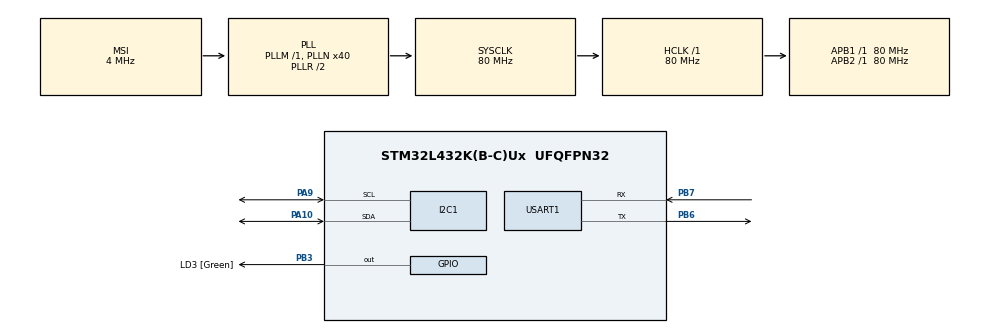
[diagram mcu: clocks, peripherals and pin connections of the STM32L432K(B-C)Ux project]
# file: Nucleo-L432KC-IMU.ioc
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Dma.Request0=USART1_RX
Dma.USART1_RX.0.Direction=DMA_PERIPH_TO_MEMORY
Dma.USART1_RX.0.Instance=DMA1_Channel5
Dma.USART1_RX.0.MemDataAlignment=DMA_MDATAALIGN_BYTE
Dma.USART1_RX.0.MemInc=DMA_MINC_ENABLE
Dma.USART1_RX.0.Mode=DMA_CIRCULAR
Dma.USART1_RX.0.PeriphDataAlignment=DMA_PDATAALIGN_BYTE
Dma.USART1_RX.0.PeriphInc=DMA_PINC_DISABLE
Dma.USART1_RX.0.Priority=DMA_PRIORITY_HIGH
FREERTOS.Mutexes01=USART1RXMutex,Static,USART1RXMutexControlBlock;I2C1Mutex,Static,I2C1MutexControlBlock;USART1TXMutex,Static,USART1TXMutexControlBlock
FREERTOS.Queues01=I2C1RXEventQueue,1,uint8_t,0,Static,I2C1RXEventQueueBuffer,I2C1RXEventQueueControlBlock;I2C1TXEventQueue,1,uint8_t,0,Static,I2C1TXEventQueueBuffer,I2C1TXEventQueueControlBlock;USART1RXEventQueue,1,uint8_t,0,Static,USART1RXEventQueueBuffer,USART1RXEventQueueControlBlock
FREERTOS.Tasks01=consoleTask,24,512,ConsoleTask,As weak,NULL,Static,consoleTaskBuffer,consoleTaskControlBlock;memsTask,24,1024,MEMSTask,As weak,NULL,Static,memsTaskBuffer,memsTaskControlBlock
FREERTOS.Timers01=taskTimer,taskTimerCb,osTimerPeriodic,As weak,NULL,Static,taskTimerControlBlock
FREERTOS.configENABLE_FPU=1
FREERTOS.configUSE_NEWLIB_REENTRANT=1
FREERTOS.configUSE_TIMERS=1
I2C1.Timing=0x10909CEC
Mcu.Family=STM32L4
Mcu.Name=STM32L432K(B-C)Ux
Mcu.Package=UFQFPN32
NVIC.DMA1_Channel5_IRQn=true\:5\:0\:false\:false\:true\:true\:false\:true\:true
NVIC.I2C1_EV_IRQn=true\:5\:0\:false\:false\:true\:true\:true\:true\:true
NVIC.PriorityGroup=NVIC_PRIORITYGROUP_4
NVIC.TIM7_IRQn=true\:15\:0\:false\:false\:true\:false\:false\:true\:true
NVIC.TimeBase=TIM7_IRQn
NVIC.TimeBaseIP=TIM7
NVIC.USART1_IRQn=true\:5\:0\:false\:false\:true\:true\:true\:true\:true
PA0.GPIO_Label=MCO [High speed clock in]
PA0.Signal=RCC_CK_IN
PA10.Mode=I2C
PA10.Signal=I2C1_SDA
PA13\ (JTMS-SWDIO).GPIO_Label=SWDIO
PA13\ (JTMS-SWDIO).Signal=SYS_JTMS-SWDIO
PA14\ (JTCK-SWCLK).GPIO_Label=SWCLK
PA14\ (JTCK-SWCLK).Signal=SYS_JTCK-SWCLK
PA15\ (JTDI).GPIO_Label=VCP_RX
PA15\ (JTDI).Signal=USART2_RX
PA2.GPIO_Label=VCP_TX
PA2.Signal=USART2_TX
PA9.Mode=I2C
PA9.Signal=I2C1_SCL
PB3\ (JTDO-TRACESWO).GPIO_Label=LD3 [Green]
PB3\ (JTDO-TRACESWO).Signal=GPIO_Output
PB6.Mode=Asynchronous
PB6.Signal=USART1_TX
PB7.Mode=Asynchronous
PB7.Signal=USART1_RX
PC14-OSC32_IN\ (PC14).Signal=RCC_OSC32_IN
PC15-OSC32_OUT\ (PC15).Signal=RCC_OSC32_OUT
ProjectManager.HeapSize=0x200
ProjectManager.StackSize=0x400
ProjectManager.TargetToolchain=STM32CubeIDE
RCC.AHBFreq_Value=80000000
RCC.APB1Freq_Value=80000000
RCC.APB1TimFreq_Value=80000000
RCC.APB2Freq_Value=80000000
RCC.APB2TimFreq_Value=80000000
RCC.CortexFreq_Value=80000000
RCC.HCLKFreq_Value=80000000
RCC.HSE_VALUE=8000000
RCC.HSI16_VALUE=16000000
RCC.HSI48_VALUE=48000000
RCC.HSI_VALUE=16000000
RCC.LSE_VALUE=32768
RCC.MSI_VALUE=4000000
RCC.PLLMUL=RCC_PLLMUL_4
RCC.PLLN=40
RCC.SYSCLKFreq_VALUE=80000000
RCC.SYSCLKSource=RCC_SYSCLKSOURCE_PLLCLK
RCC.VCOOutputFreq_Value=160000000
USART1.VirtualMode-Asynchronous=VM_ASYNC
VP_CRC_VS_CRC.Mode=CRC_Activate
VP_FREERTOS_VS_CMSIS_V2.Mode=CMSIS_V2
VP_SYS_VS_tim7.Mode=TIM7
board=NUCLEO-L432KC

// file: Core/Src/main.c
/* USER CODE BEGIN Header */
/**
  ******************************************************************************
  * @file           : main.c
  * @brief          : Main program body
  ******************************************************************************
  * @attention
  *
  * Copyright (c) 2023 STMicroelectronics.
  * All rights reserved.
  *
  * This software is licensed under terms that can be found in the LICENSE file
  * in the root directory of this software component.
  * If no LICENSE file comes with this software, it is provided AS-IS.
  *
  ******************************************************************************
  */
/* USER CODE END Header */
#include "main.h"
#include "cmsis_os.h"
#include "crc.h"
#include "dma.h"
#include "i2c.h"
#include "usart.h"
#include "gpio.h"

/* USER CODE BEGIN Includes */
#include "appMotionFX.h"
/* USER CODE END Includes */

void SystemClock_Config(void);
void MX_FREERTOS_Init(void);

int main(void)
{

  /* MCU Configuration--------------------------------------------------------*/

  /* Reset of all peripherals, Initializes the Flash interface and the Systick. */
  HAL_Init();

  /* Configure the system clock */
  SystemClock_Config();

  /* Initialize all configured peripherals */
  MX_GPIO_Init();
  MX_DMA_Init();
  MX_I2C1_Init();
  MX_USART1_UART_Init();
  MX_CRC_Init();

  /* Init scheduler */
  osKernelInitialize();  /* Call init function for freertos objects (in freertos.c) */
  MX_FREERTOS_Init();

  /* Start scheduler */
  osKernelStart();

  /* We should never get here as control is now taken by the scheduler */
  /* Infinite loop */
  while (1)
  {

  }
}

void SystemClock_Config(void)
{
  RCC_OscInitTypeDef RCC_OscInitStruct = {0};
  RCC_ClkInitTypeDef RCC_ClkInitStruct = {0};

  /** Configure the main internal regulator output voltage
  */
  if (HAL_PWREx_ControlVoltageScaling(PWR_REGULATOR_VOLTAGE_SCALE1) != HAL_OK)
  {
    Error_Handler();
  }

  /** Initializes the RCC Oscillators according to the specified parameters
  * in the RCC_OscInitTypeDef structure.
  */
  RCC_OscInitStruct.OscillatorType = RCC_OSCILLATORTYPE_MSI;
  RCC_OscInitStruct.MSIState = RCC_MSI_ON;
  RCC_OscInitStruct.MSICalibrationValue = 0;
  RCC_OscInitStruct.MSIClockRange = RCC_MSIRANGE_6;
  RCC_OscInitStruct.PLL.PLLState = RCC_PLL_ON;
  RCC_OscInitStruct.PLL.PLLSource = RCC_PLLSOURCE_MSI;
  RCC_OscInitStruct.PLL.PLLM = 1;
  RCC_OscInitStruct.PLL.PLLN = 40;
  RCC_OscInitStruct.PLL.PLLP = RCC_PLLP_DIV7;
  RCC_OscInitStruct.PLL.PLLQ = RCC_PLLQ_DIV2;
  RCC_OscInitStruct.PLL.PLLR = RCC_PLLR_DIV2;
  if (HAL_RCC_OscConfig(&RCC_OscInitStruct) != HAL_OK)
  {
    Error_Handler();
  }

  /** Initializes the CPU, AHB and APB buses clocks
  */
  RCC_ClkInitStruct.ClockType = RCC_CLOCKTYPE_HCLK|RCC_CLOCKTYPE_SYSCLK
                              |RCC_CLOCKTYPE_PCLK1|RCC_CLOCKTYPE_PCLK2;
  RCC_ClkInitStruct.SYSCLKSource = RCC_SYSCLKSOURCE_PLLCLK;
  RCC_ClkInitStruct.AHBCLKDivider = RCC_SYSCLK_DIV1;
  RCC_ClkInitStruct.APB1CLKDivider = RCC_HCLK_DIV1;
  RCC_ClkInitStruct.APB2CLKDivider = RCC_HCLK_DIV1;

  if (HAL_RCC_ClockConfig(&RCC_ClkInitStruct, FLASH_LATENCY_4) != HAL_OK)
  {
    Error_Handler();
  }
}

void HAL_TIM_PeriodElapsedCallback(TIM_HandleTypeDef *htim)
{
  if (htim->Instance == TIM7) {
    HAL_IncTick();
  }
}

void Error_Handler(void)
{
  __disable_irq();
  while (1)
  {
  }
}

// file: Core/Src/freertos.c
/* USER CODE BEGIN Header */
/**
  ******************************************************************************
  * File Name          : freertos.c
  * Description        : Code for freertos applications
  ******************************************************************************
  * @attention
  *
  * Copyright (c) 2023 STMicroelectronics.
  * All rights reserved.
  *
  * This software is licensed under terms that can be found in the LICENSE file
  * in the root directory of this software component.
  * If no LICENSE file comes with this software, it is provided AS-IS.
  *
  ******************************************************************************
  */
/* USER CODE END Header */

#include "FreeRTOS.h"
#include "task.h"
#include "main.h"
#include "cmsis_os.h"

/* USER CODE BEGIN Includes */
#include "appLSM9DS1.h"
#include "appI2C.h"
#include "appUSART.h"
#include "console.h"
/* USER CODE END Includes */

typedef StaticTask_t osStaticThreadDef_t;
typedef StaticQueue_t osStaticMessageQDef_t;
typedef StaticTimer_t osStaticTimerDef_t;
typedef StaticSemaphore_t osStaticMutexDef_t;

/* Definitions for consoleTask */
osThreadId_t consoleTaskHandle;
uint32_t consoleTaskBuffer[ 512 ];
osStaticThreadDef_t consoleTaskControlBlock;
const osThreadAttr_t consoleTask_attributes = {
  .name = "consoleTask",
  .cb_mem = &consoleTaskControlBlock,
  .cb_size = sizeof(consoleTaskControlBlock),
  .stack_mem = &consoleTaskBuffer[0],
  .stack_size = sizeof(consoleTaskBuffer),
  .priority = (osPriority_t) osPriorityNormal,
};
/* Definitions for memsTask */
osThreadId_t memsTaskHandle;
uint32_t memsTaskBuffer[ 1024 ];
osStaticThreadDef_t memsTaskControlBlock;
const osThreadAttr_t memsTask_attributes = {
  .name = "memsTask",
  .cb_mem = &memsTaskControlBlock,
  .cb_size = sizeof(memsTaskControlBlock),
  .stack_mem = &memsTaskBuffer[0],
  .stack_size = sizeof(memsTaskBuffer),
  .priority = (osPriority_t) osPriorityNormal,
};
/* Definitions for I2C1RXEventQueue */
osMessageQueueId_t I2C1RXEventQueueHandle;
uint8_t I2C1RXEventQueueBuffer[ 1 * sizeof( uint8_t ) ];
osStaticMessageQDef_t I2C1RXEventQueueControlBlock;
const osMessageQueueAttr_t I2C1RXEventQueue_attributes = {
  .name = "I2C1RXEventQueue",
  .cb_mem = &I2C1RXEventQueueControlBlock,
  .cb_size = sizeof(I2C1RXEventQueueControlBlock),
  .mq_mem = &I2C1RXEventQueueBuffer,
  .mq_size = sizeof(I2C1RXEventQueueBuffer)
};
/* Definitions for I2C1TXEventQueue */
osMessageQueueId_t I2C1TXEventQueueHandle;
uint8_t I2C1TXEventQueueBuffer[ 1 * sizeof( uint8_t ) ];
osStaticMessageQDef_t I2C1TXEventQueueControlBlock;
const osMessageQueueAttr_t I2C1TXEventQueue_attributes = {
  .name = "I2C1TXEventQueue",
  .cb_mem = &I2C1TXEventQueueControlBlock,
  .cb_size = sizeof(I2C1TXEventQueueControlBlock),
  .mq_mem = &I2C1TXEventQueueBuffer,
  .mq_size = sizeof(I2C1TXEventQueueBuffer)
};
/* Definitions for USART1RXEventQueue */
osMessageQueueId_t USART1RXEventQueueHandle;
uint8_t USART1RXEventQueueBuffer[ 1 * sizeof( uint8_t ) ];
osStaticMessageQDef_t USART1RXEventQueueControlBlock;
const osMessageQueueAttr_t USART1RXEventQueue_attributes = {
  .name = "USART1RXEventQueue",
  .cb_mem = &USART1RXEventQueueControlBlock,
  .cb_size = sizeof(USART1RXEventQueueControlBlock),
  .mq_mem = &USART1RXEventQueueBuffer,
  .mq_size = sizeof(USART1RXEventQueueBuffer)
};
/* Definitions for taskTimer */
osTimerId_t taskTimerHandle;
osStaticTimerDef_t taskTimerControlBlock;
const osTimerAttr_t taskTimer_attributes = {
  .name = "taskTimer",
  .cb_mem = &taskTimerControlBlock,
  .cb_size = sizeof(taskTimerControlBlock),
};
/* Definitions for USART1RXMutex */
osMutexId_t USART1RXMutexHandle;
osStaticMutexDef_t USART1RXMutexControlBlock;
const osMutexAttr_t USART1RXMutex_attributes = {
  .name = "USART1RXMutex",
  .cb_mem = &USART1RXMutexControlBlock,
  .cb_size = sizeof(USART1RXMutexControlBlock),
};
/* Definitions for I2C1Mutex */
osMutexId_t I2C1MutexHandle;
osStaticMutexDef_t I2C1MutexControlBlock;
const osMutexAttr_t I2C1Mutex_attributes = {
  .name = "I2C1Mutex",
  .cb_mem = &I2C1MutexControlBlock,
  .cb_size = sizeof(I2C1MutexControlBlock),
};
/* Definitions for USART1TXMutex */
osMutexId_t USART1TXMutexHandle;
osStaticMutexDef_t USART1TXMutexControlBlock;
const osMutexAttr_t USART1TXMutex_attributes = {
  .name = "USART1TXMutex",
  .cb_mem = &USART1TXMutexControlBlock,
  .cb_size = sizeof(USART1TXMutexControlBlock),
};

void ConsoleTask(void *argument);
void MEMSTask(void *argument);
void taskTimerCb(void *argument);

void MX_FREERTOS_Init(void); /* (MISRA C 2004 rule 8.1) */

void MX_FREERTOS_Init(void) {
  /* Create the mutex(es) */
  /* creation of USART1RXMutex */
  USART1RXMutexHandle = osMutexNew(&USART1RXMutex_attributes);

  /* creation of I2C1Mutex */
  I2C1MutexHandle = osMutexNew(&I2C1Mutex_attributes);

  /* creation of USART1TXMutex */
  USART1TXMutexHandle = osMutexNew(&USART1TXMutex_attributes);

  /* Create the timer(s) */
  /* creation of taskTimer */
  taskTimerHandle = osTimerNew(taskTimerCb, osTimerPeriodic, NULL, &taskTimer_attributes);

  /* Create the queue(s) */
  /* creation of I2C1RXEventQueue */
  I2C1RXEventQueueHandle = osMessageQueueNew (1, sizeof(uint8_t), &I2C1RXEventQueue_attributes);

  /* creation of I2C1TXEventQueue */
  I2C1TXEventQueueHandle = osMessageQueueNew (1, sizeof(uint8_t), &I2C1TXEventQueue_attributes);

  /* creation of USART1RXEventQueue */
  USART1RXEventQueueHandle = osMessageQueueNew (1, sizeof(uint8_t), &USART1RXEventQueue_attributes);

  /* USER CODE BEGIN RTOS_QUEUES */
  /* add queues, ... */
  USART1Init();
  I2C1Init();
  /* USER CODE END RTOS_QUEUES */

  /* Create the thread(s) */
  /* creation of consoleTask */
  consoleTaskHandle = osThreadNew(ConsoleTask, NULL, &consoleTask_attributes);

  /* creation of memsTask */
  memsTaskHandle = osThreadNew(MEMSTask, NULL, &memsTask_attributes);

}

__weak void ConsoleTask(void *argument)
{
  for(;;)
  {
    osDelay(1);
  }
}

__weak void MEMSTask(void *argument)
{
  for(;;)
  {
    osDelay(1);
  }
}

/* taskTimerCb function */
__weak void taskTimerCb(void *argument)
{
  /* USER CODE BEGIN taskTimerCb */
	osThreadResume(memsTaskHandle);
  /* USER CODE END taskTimerCb */
}
